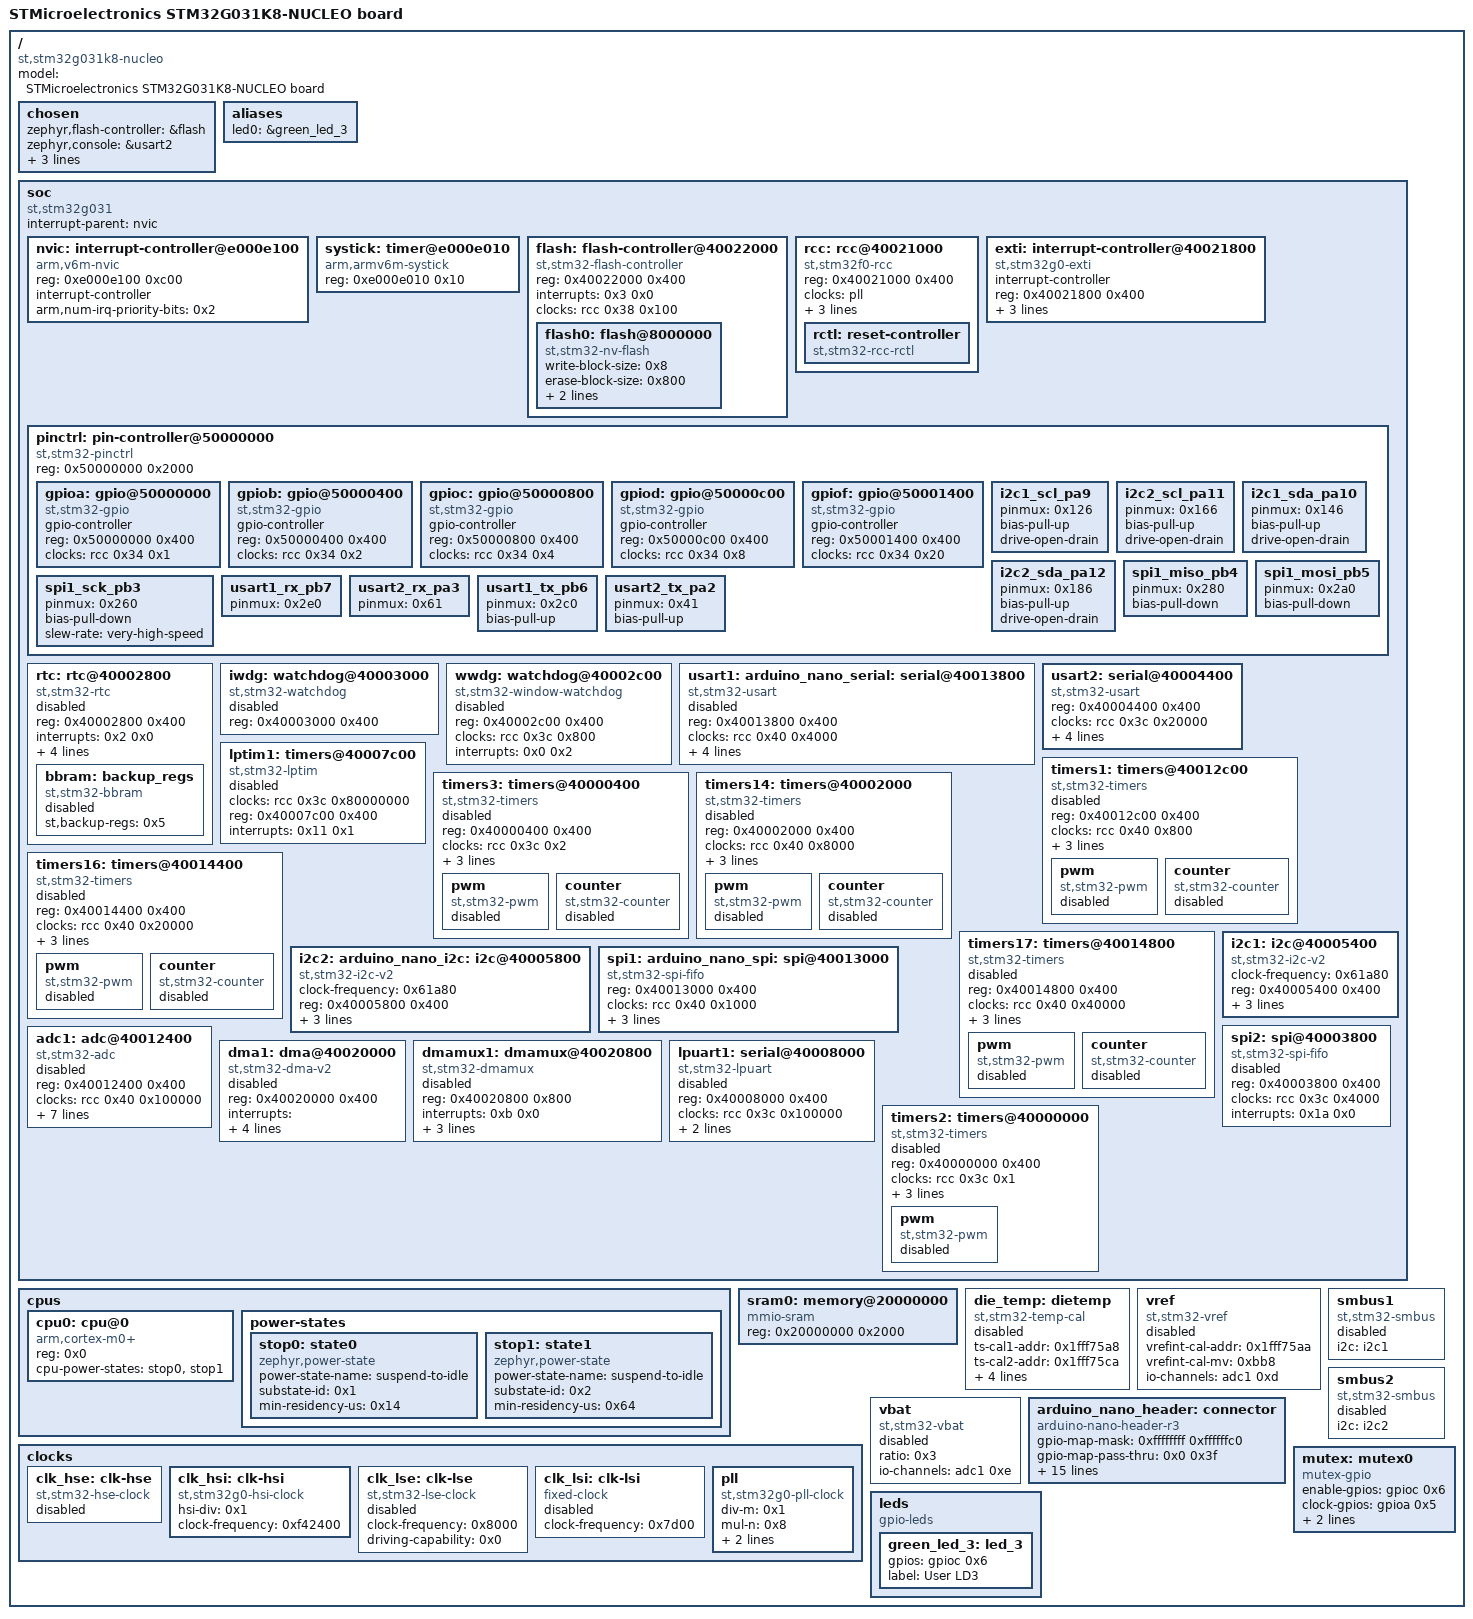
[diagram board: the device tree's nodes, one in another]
/dts-v1/;

/ {
	#address-cells = < 0x1 >;
	#size-cells = < 0x1 >;
	model = "STMicroelectronics STM32G031K8-NUCLEO board";
	compatible = "st,stm32g031k8-nucleo";
	chosen {
		zephyr,flash-controller = &flash;
		zephyr,console = &usart2;
		zephyr,shell-uart = &usart2;
		zephyr,sram = &sram0;
		zephyr,flash = &flash0;
	};
	aliases {
		led0 = &green_led_3;
	};
	soc {
		#address-cells = < 0x1 >;
		#size-cells = < 0x1 >;
		compatible = "st,stm32g031", "st,stm32g0", "simple-bus";
		interrupt-parent = < &nvic >;
		ranges;
		nvic: interrupt-controller@e000e100 {
			#address-cells = < 0x1 >;
			compatible = "arm,v6m-nvic";
			reg = < 0xe000e100 0xc00 >;
			interrupt-controller;
			#interrupt-cells = < 0x2 >;
			arm,num-irq-priority-bits = < 0x2 >;
			phandle = < 0x1 >;
		};
		systick: timer@e000e010 {
			compatible = "arm,armv6m-systick";
			reg = < 0xe000e010 0x10 >;
		};
		flash: flash-controller@40022000 {
			compatible = "st,stm32-flash-controller", "st,stm32g0-flash-controller";
			reg = < 0x40022000 0x400 >;
			interrupts = < 0x3 0x0 >;
			clocks = < &rcc 0x38 0x100 >;
			#address-cells = < 0x1 >;
			#size-cells = < 0x1 >;
			flash0: flash@8000000 {
				compatible = "st,stm32-nv-flash", "soc-nv-flash";
				write-block-size = < 0x8 >;
				erase-block-size = < 0x800 >;
				max-erase-time = < 0x28 >;
				reg = < 0x8000000 0x10000 >;
			};
		};
		rcc: rcc@40021000 {
			compatible = "st,stm32f0-rcc";
			#clock-cells = < 0x2 >;
			reg = < 0x40021000 0x400 >;
			clocks = < &pll >;
			clock-frequency = < 0x3d09000 >;
			ahb-prescaler = < 0x1 >;
			apb1-prescaler = < 0x1 >;
			phandle = < 0x2 >;
			rctl: reset-controller {
				compatible = "st,stm32-rcc-rctl";
				#reset-cells = < 0x1 >;
				phandle = < 0x4 >;
			};
		};
		exti: interrupt-controller@40021800 {
			compatible = "st,stm32g0-exti", "st,stm32-exti";
			interrupt-controller;
			#interrupt-cells = < 0x1 >;
			#address-cells = < 0x1 >;
			reg = < 0x40021800 0x400 >;
			num-lines = < 0x10 >;
			interrupts = < 0x5 0x0 >, < 0x6 0x0 >, < 0x7 0x0 >;
			interrupt-names = "line0-1", "line2-3", "line4-15";
			line-ranges = < 0x0 0x2 >, < 0x2 0x2 >, < 0x4 0xc >;
		};
		pinctrl: pin-controller@50000000 {
			compatible = "st,stm32-pinctrl";
			#address-cells = < 0x1 >;
			#size-cells = < 0x1 >;
			reg = < 0x50000000 0x2000 >;
			gpioa: gpio@50000000 {
				compatible = "st,stm32-gpio";
				gpio-controller;
				#gpio-cells = < 0x2 >;
				reg = < 0x50000000 0x400 >;
				clocks = < &rcc 0x34 0x1 >;
				phandle = < 0x17 >;
			};
			gpiob: gpio@50000400 {
				compatible = "st,stm32-gpio";
				gpio-controller;
				#gpio-cells = < 0x2 >;
				reg = < 0x50000400 0x400 >;
				clocks = < &rcc 0x34 0x2 >;
				phandle = < 0x16 >;
			};
			gpioc: gpio@50000800 {
				compatible = "st,stm32-gpio";
				gpio-controller;
				#gpio-cells = < 0x2 >;
				reg = < 0x50000800 0x400 >;
				clocks = < &rcc 0x34 0x4 >;
				phandle = < 0x18 >;
			};
			gpiod: gpio@50000c00 {
				compatible = "st,stm32-gpio";
				gpio-controller;
				#gpio-cells = < 0x2 >;
				reg = < 0x50000c00 0x400 >;
				clocks = < &rcc 0x34 0x8 >;
			};
			gpiof: gpio@50001400 {
				compatible = "st,stm32-gpio";
				gpio-controller;
				#gpio-cells = < 0x2 >;
				reg = < 0x50001400 0x400 >;
				clocks = < &rcc 0x34 0x20 >;
			};
			i2c1_scl_pa9: i2c1_scl_pa9 {
				pinmux = < 0x126 >;
				bias-pull-up;
				drive-open-drain;
				phandle = < 0x9 >;
			};
			i2c2_scl_pa11: i2c2_scl_pa11 {
				pinmux = < 0x166 >;
				bias-pull-up;
				drive-open-drain;
				phandle = < 0xb >;
			};
			i2c1_sda_pa10: i2c1_sda_pa10 {
				pinmux = < 0x146 >;
				bias-pull-up;
				drive-open-drain;
				phandle = < 0xa >;
			};
			i2c2_sda_pa12: i2c2_sda_pa12 {
				pinmux = < 0x186 >;
				bias-pull-up;
				drive-open-drain;
				phandle = < 0xc >;
			};
			spi1_miso_pb4: spi1_miso_pb4 {
				pinmux = < 0x280 >;
				bias-pull-down;
				phandle = < 0xe >;
			};
			spi1_mosi_pb5: spi1_mosi_pb5 {
				pinmux = < 0x2a0 >;
				bias-pull-down;
				phandle = < 0xf >;
			};
			spi1_sck_pb3: spi1_sck_pb3 {
				pinmux = < 0x260 >;
				bias-pull-down;
				slew-rate = "very-high-speed";
				phandle = < 0xd >;
			};
			usart1_rx_pb7: usart1_rx_pb7 {
				pinmux = < 0x2e0 >;
				phandle = < 0x6 >;
			};
			usart2_rx_pa3: usart2_rx_pa3 {
				pinmux = < 0x61 >;
				phandle = < 0x8 >;
			};
			usart1_tx_pb6: usart1_tx_pb6 {
				pinmux = < 0x2c0 >;
				bias-pull-up;
				phandle = < 0x5 >;
			};
			usart2_tx_pa2: usart2_tx_pa2 {
				pinmux = < 0x41 >;
				bias-pull-up;
				phandle = < 0x7 >;
			};
		};
		rtc: rtc@40002800 {
			compatible = "st,stm32-rtc";
			reg = < 0x40002800 0x400 >;
			interrupts = < 0x2 0x0 >;
			clocks = < &rcc 0x3c 0x400 >;
			prescaler = < 0x8000 >;
			alarms-count = < 0x2 >;
			alrm-exti-line = < 0x13 >;
			status = "disabled";
			bbram: backup_regs {
				compatible = "st,stm32-bbram";
				st,backup-regs = < 0x5 >;
				status = "disabled";
			};
		};
		iwdg: watchdog@40003000 {
			compatible = "st,stm32-watchdog";
			reg = < 0x40003000 0x400 >;
			status = "disabled";
		};
		wwdg: watchdog@40002c00 {
			compatible = "st,stm32-window-watchdog";
			reg = < 0x40002c00 0x400 >;
			clocks = < &rcc 0x3c 0x800 >;
			interrupts = < 0x0 0x2 >;
			status = "disabled";
		};
		usart1: arduino_nano_serial: serial@40013800 {
			compatible = "st,stm32-usart", "st,stm32-uart";
			reg = < 0x40013800 0x400 >;
			clocks = < &rcc 0x40 0x4000 >;
			resets = < &rctl 0x60e >;
			interrupts = < 0x1b 0x0 >;
			status = "disabled";
			pinctrl-0 = < &usart1_tx_pb6 &usart1_rx_pb7 >;
			pinctrl-names = "default";
			current-speed = < 0x1c200 >;
		};
		usart2: serial@40004400 {
			compatible = "st,stm32-usart", "st,stm32-uart";
			reg = < 0x40004400 0x400 >;
			clocks = < &rcc 0x3c 0x20000 >;
			resets = < &rctl 0x591 >;
			interrupts = < 0x1c 0x0 >;
			status = "okay";
			pinctrl-0 = < &usart2_tx_pa2 &usart2_rx_pa3 >;
			pinctrl-names = "default";
			current-speed = < 0x1c200 >;
		};
		lptim1: timers@40007c00 {
			compatible = "st,stm32-lptim";
			clocks = < &rcc 0x3c 0x80000000 >;
			#address-cells = < 0x1 >;
			#size-cells = < 0x0 >;
			reg = < 0x40007c00 0x400 >;
			interrupts = < 0x11 0x1 >;
			interrupt-names = "wakeup";
			status = "disabled";
		};
		timers1: timers@40012c00 {
			compatible = "st,stm32-timers";
			reg = < 0x40012c00 0x400 >;
			clocks = < &rcc 0x40 0x800 >;
			resets = < &rctl 0x60b >;
			interrupts = < 0xd 0x0 >, < 0xe 0x0 >;
			interrupt-names = "brk_up_trg_com", "cc";
			st,prescaler = < 0x0 >;
			status = "disabled";
			pwm {
				compatible = "st,stm32-pwm";
				status = "disabled";
				#pwm-cells = < 0x3 >;
			};
			counter {
				compatible = "st,stm32-counter";
				status = "disabled";
			};
		};
		timers3: timers@40000400 {
			compatible = "st,stm32-timers";
			reg = < 0x40000400 0x400 >;
			clocks = < &rcc 0x3c 0x2 >;
			resets = < &rctl 0x581 >;
			interrupts = < 0x10 0x0 >;
			interrupt-names = "global";
			st,prescaler = < 0x0 >;
			status = "disabled";
			pwm {
				compatible = "st,stm32-pwm";
				status = "disabled";
				#pwm-cells = < 0x3 >;
			};
			counter {
				compatible = "st,stm32-counter";
				status = "disabled";
			};
		};
		timers14: timers@40002000 {
			compatible = "st,stm32-timers";
			reg = < 0x40002000 0x400 >;
			clocks = < &rcc 0x40 0x8000 >;
			resets = < &rctl 0x60f >;
			interrupts = < 0x13 0x0 >;
			interrupt-names = "global";
			st,prescaler = < 0x0 >;
			status = "disabled";
			pwm {
				compatible = "st,stm32-pwm";
				status = "disabled";
				#pwm-cells = < 0x3 >;
			};
			counter {
				compatible = "st,stm32-counter";
				status = "disabled";
			};
		};
		timers16: timers@40014400 {
			compatible = "st,stm32-timers";
			reg = < 0x40014400 0x400 >;
			clocks = < &rcc 0x40 0x20000 >;
			resets = < &rctl 0x611 >;
			interrupts = < 0x15 0x0 >;
			interrupt-names = "global";
			st,prescaler = < 0x0 >;
			status = "disabled";
			pwm {
				compatible = "st,stm32-pwm";
				status = "disabled";
				#pwm-cells = < 0x3 >;
			};
			counter {
				compatible = "st,stm32-counter";
				status = "disabled";
			};
		};
		timers17: timers@40014800 {
			compatible = "st,stm32-timers";
			reg = < 0x40014800 0x400 >;
			clocks = < &rcc 0x40 0x40000 >;
			resets = < &rctl 0x612 >;
			interrupts = < 0x16 0x0 >;
			interrupt-names = "global";
			st,prescaler = < 0x0 >;
			status = "disabled";
			pwm {
				compatible = "st,stm32-pwm";
				status = "disabled";
				#pwm-cells = < 0x3 >;
			};
			counter {
				compatible = "st,stm32-counter";
				status = "disabled";
			};
		};
		i2c1: i2c@40005400 {
			compatible = "st,stm32-i2c-v2";
			clock-frequency = < 0x61a80 >;
			#address-cells = < 0x1 >;
			#size-cells = < 0x0 >;
			reg = < 0x40005400 0x400 >;
			clocks = < &rcc 0x3c 0x200000 >;
			interrupts = < 0x17 0x0 >;
			interrupt-names = "combined";
			status = "okay";
			pinctrl-0 = < &i2c1_scl_pa9 &i2c1_sda_pa10 >;
			pinctrl-names = "default";
			phandle = < 0x14 >;
		};
		i2c2: arduino_nano_i2c: i2c@40005800 {
			compatible = "st,stm32-i2c-v2";
			clock-frequency = < 0x61a80 >;
			#address-cells = < 0x1 >;
			#size-cells = < 0x0 >;
			reg = < 0x40005800 0x400 >;
			clocks = < &rcc 0x3c 0x400000 >;
			interrupts = < 0x18 0x0 >;
			interrupt-names = "combined";
			status = "okay";
			pinctrl-0 = < &i2c2_scl_pa11 &i2c2_sda_pa12 >;
			pinctrl-names = "default";
			phandle = < 0x15 >;
		};
		spi1: arduino_nano_spi: spi@40013000 {
			compatible = "st,stm32-spi-fifo", "st,stm32-spi";
			#address-cells = < 0x1 >;
			#size-cells = < 0x0 >;
			reg = < 0x40013000 0x400 >;
			clocks = < &rcc 0x40 0x1000 >;
			interrupts = < 0x19 0x0 >;
			status = "okay";
			pinctrl-0 = < &spi1_sck_pb3 &spi1_miso_pb4 &spi1_mosi_pb5 >;
			pinctrl-names = "default";
		};
		spi2: spi@40003800 {
			compatible = "st,stm32-spi-fifo", "st,stm32-spi";
			#address-cells = < 0x1 >;
			#size-cells = < 0x0 >;
			reg = < 0x40003800 0x400 >;
			clocks = < &rcc 0x3c 0x4000 >;
			interrupts = < 0x1a 0x0 >;
			status = "disabled";
		};
		adc1: adc@40012400 {
			compatible = "st,stm32-adc";
			reg = < 0x40012400 0x400 >;
			clocks = < &rcc 0x40 0x100000 >;
			interrupts = < 0xc 0x0 >;
			status = "disabled";
			#io-channel-cells = < 0x1 >;
			resolutions = < 0x60630c 0x51630c 0x42630c 0x33630c >;
			sampling-times = < 0x3 0x5 0x8 0xd 0x14 0x28 0x50 0xa1 >;
			num-sampling-time-common-channels = < 0x2 >;
			st,adc-sequencer = < 0x0 >;
			phandle = < 0x13 >;
		};
		dma1: dma@40020000 {
			compatible = "st,stm32-dma-v2";
			#dma-cells = < 0x3 >;
			reg = < 0x40020000 0x400 >;
			interrupts = < 0x9 0x0 0xa 0x0 0xa 0x0 0xb 0x0 0xb 0x0 >;
			clocks = < &rcc 0x38 0x1 >;
			dma-requests = < 0x5 >;
			dma-offset = < 0x0 >;
			status = "disabled";
		};
		dmamux1: dmamux@40020800 {
			compatible = "st,stm32-dmamux";
			#dma-cells = < 0x3 >;
			reg = < 0x40020800 0x800 >;
			interrupts = < 0xb 0x0 >;
			dma-channels = < 0x5 >;
			dma-generators = < 0x4 >;
			dma-requests = < 0x31 >;
			status = "disabled";
		};
		lpuart1: serial@40008000 {
			compatible = "st,stm32-lpuart", "st,stm32-uart";
			reg = < 0x40008000 0x400 >;
			clocks = < &rcc 0x3c 0x100000 >;
			resets = < &rctl 0x594 >;
			interrupts = < 0x1d 0x0 >;
			status = "disabled";
		};
		timers2: timers@40000000 {
			compatible = "st,stm32-timers";
			reg = < 0x40000000 0x400 >;
			clocks = < &rcc 0x3c 0x1 >;
			resets = < &rctl 0x580 >;
			interrupts = < 0xf 0x0 >;
			interrupt-names = "global";
			st,prescaler = < 0x0 >;
			status = "disabled";
			pwm {
				compatible = "st,stm32-pwm";
				status = "disabled";
				#pwm-cells = < 0x3 >;
			};
		};
	};
	cpus {
		#address-cells = < 0x1 >;
		#size-cells = < 0x0 >;
		cpu0: cpu@0 {
			device_type = "cpu";
			compatible = "arm,cortex-m0+";
			reg = < 0x0 >;
			cpu-power-states = < &stop0 &stop1 >;
		};
		power-states {
			stop0: state0 {
				compatible = "zephyr,power-state";
				power-state-name = "suspend-to-idle";
				substate-id = < 0x1 >;
				min-residency-us = < 0x14 >;
				phandle = < 0x10 >;
			};
			stop1: state1 {
				compatible = "zephyr,power-state";
				power-state-name = "suspend-to-idle";
				substate-id = < 0x2 >;
				min-residency-us = < 0x64 >;
				phandle = < 0x11 >;
			};
		};
	};
	sram0: memory@20000000 {
		compatible = "mmio-sram";
		reg = < 0x20000000 0x2000 >;
	};
	clocks {
		clk_hse: clk-hse {
			#clock-cells = < 0x0 >;
			compatible = "st,stm32-hse-clock";
			status = "disabled";
		};
		clk_hsi: clk-hsi {
			#clock-cells = < 0x0 >;
			compatible = "st,stm32g0-hsi-clock";
			hsi-div = < 0x1 >;
			clock-frequency = < 0xf42400 >;
			status = "okay";
			phandle = < 0x12 >;
		};
		clk_lse: clk-lse {
			#clock-cells = < 0x0 >;
			compatible = "st,stm32-lse-clock";
			clock-frequency = < 0x8000 >;
			driving-capability = < 0x0 >;
			status = "disabled";
		};
		clk_lsi: clk-lsi {
			#clock-cells = < 0x0 >;
			compatible = "fixed-clock";
			clock-frequency = < 0x7d00 >;
			status = "disabled";
		};
		pll: pll {
			#clock-cells = < 0x0 >;
			compatible = "st,stm32g0-pll-clock";
			status = "okay";
			div-m = < 0x1 >;
			mul-n = < 0x8 >;
			div-r = < 0x2 >;
			clocks = < &clk_hsi >;
			phandle = < 0x3 >;
		};
	};
	die_temp: dietemp {
		compatible = "st,stm32-temp-cal";
		ts-cal1-addr = < 0x1fff75a8 >;
		ts-cal2-addr = < 0x1fff75ca >;
		ts-cal1-temp = < 0x1e >;
		ts-cal2-temp = < 0x82 >;
		ts-cal-vrefanalog = < 0xbb8 >;
		io-channels = < &adc1 0xc >;
		status = "disabled";
	};
	vref: vref {
		compatible = "st,stm32-vref";
		vrefint-cal-addr = < 0x1fff75aa >;
		vrefint-cal-mv = < 0xbb8 >;
		io-channels = < &adc1 0xd >;
		status = "disabled";
	};
	vbat: vbat {
		compatible = "st,stm32-vbat";
		ratio = < 0x3 >;
		io-channels = < &adc1 0xe >;
		status = "disabled";
	};
	smbus1: smbus1 {
		compatible = "st,stm32-smbus";
		#address-cells = < 0x1 >;
		#size-cells = < 0x0 >;
		i2c = < &i2c1 >;
		status = "disabled";
	};
	smbus2: smbus2 {
		compatible = "st,stm32-smbus";
		#address-cells = < 0x1 >;
		#size-cells = < 0x0 >;
		i2c = < &i2c2 >;
		status = "disabled";
	};
	arduino_nano_header: connector {
		compatible = "arduino-nano-header-r3";
		#gpio-cells = < 0x2 >;
		gpio-map-mask = < 0xffffffff 0xffffffc0 >;
		gpio-map-pass-thru = < 0x0 0x3f >;
		gpio-map = < 0x0 0x0 &gpiob 0x7 0x0 >, < 0x1 0x0 &gpiob 0x6 0x0 >, < 0x2 0x0 &gpioa 0xf 0x0 >, < 0x3 0x0 &gpiob 0x1 0x0 >, < 0x4 0x0 &gpioa 0xa 0x0 >, < 0x5 0x0 &gpioa 0x9 0x0 >, < 0x6 0x0 &gpiob 0x0 0x0 >, < 0x7 0x0 &gpiob 0x2 0x0 >, < 0x8 0x0 &gpiob 0x8 0x0 >, < 0x9 0x0 &gpioa 0x8 0x0 >, < 0xa 0x0 &gpiob 0x9 0x0 >, < 0xb 0x0 &gpiob 0x5 0x0 >, < 0xc 0x0 &gpiob 0x4 0x0 >, < 0xd 0x0 &gpiob 0x3 0x0 >, < 0xe 0x0 &gpioa 0x0 0x0 >, < 0xf 0x0 &gpioa 0x1 0x0 >, < 0x10 0x0 &gpioa 0x4 0x0 >, < 0x11 0x0 &gpioa 0x5 0x0 >, < 0x12 0x0 &gpioa 0xc 0x0 >, < 0x13 0x0 &gpioa 0xb 0x0 >, < 0x14 0x0 &gpioa 0x6 0x0 >, < 0x15 0x0 &gpioa 0x7 0x0 >;
	};
	leds: leds {
		compatible = "gpio-leds";
		green_led_3: led_3 {
			gpios = < &gpioc 0x6 0x0 >;
			label = "User LD3";
		};
	};
	mutex: mutex0 {
		compatible = "mutex-gpio";
		enable-gpios = < &gpioc 0x6 0x0 >;
		clock-gpios = < &gpioa 0x5 0x0 >;
		data-gpios = < &gpioa 0x6 0x0 >;
		reset-gpios = < &gpioa 0x7 0x0 >;
	};
};
